# nrf7120E_enga_wificore register map
Vendor: Nordic Semiconductor; Series: nrf71; File version: 1
Registers are 32-bit, read-write, reset 0x0 unless marked. A register's access mark holds for its fields unless they carry their own. Offsets are from the block's base; [hi:lo] are bit positions; lines under a group give offsets from that group; {n}, {i} and the like mark numbered series; 'fields as' and 'values as' point back to an identical list.

## PCGCM_LRC0 — PCGC Master
Base 0x4800C000
{0xE0+4i} SETPWRCONTHRESHOLDBASE[{i}] (i=0..2) — Description collection: Set power consumption threshold base for power source / regulator n
  [3:0] SETPWRCONTHRESHOLDBASE
{0x100+4i} SETPOWERCONSUMPTIONBASE[{i}] (i=0..1) — Description collection: Set power consumption base for power/clock pair n
  [3:0] POWERREQUIREMENT
0xC00 UNLOCKBACKDOORS
  [15:0] UNLOCKBACKDOORS — Write: 0x00009375 to lock/unlock backdoors Read: 0x00000001 if backdoors is enabled Read: 0x00000000 if backdoors is disabled
0xC04 ENABLEPOWERREGFORCE
  [2:0] ENABLEPOWERREGFORCE
0xC08 POWERREGFORCE — Force reg
  [2:0] POWERREGFORCEREG
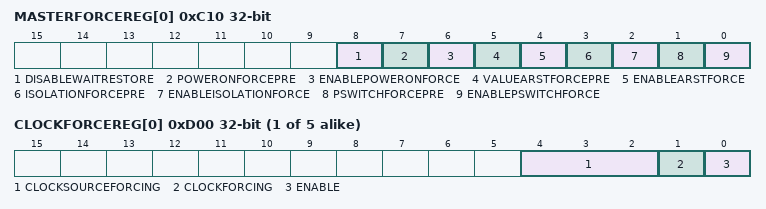
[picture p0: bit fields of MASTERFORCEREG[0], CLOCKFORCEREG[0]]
{0xC10+4i} MASTERFORCEREG[{i}] (i=0..0) — Description collection: Force reg
  [8] DISABLEWAITRESTORE — Turn off waiting for arst deactivation before retention restore
    1=Disable (Turn off waiting for arst deactivation before retention restore); 0=Enable (Wait for arst deactivation before retention restore)
  [7] POWERONFORCEPRE
  [6] ENABLEPOWERONFORCE
  [5] VALUEARSTFORCEPRE
  [4] ENABLEARSTFORCE
  [3] ISOLATIONFORCEPRE
  [2] ENABLEISOLATIONFORCE
  [1] PSWITCHFORCEPRE
  [0] ENABLEPSWITCHFORCE
{0xD00+4i} CLOCKFORCEREG[{i}] (i=0..4) — Description collection: Force clock n
  [4:2] CLOCKSOURCEFORCING
  [1] CLOCKFORCING
  [0] ENABLE — Enable clock forcing

## ANTSWC — Antenna switch controller
Base 0x4800D000
0x400 ERRORSTATUS group — Unspecified
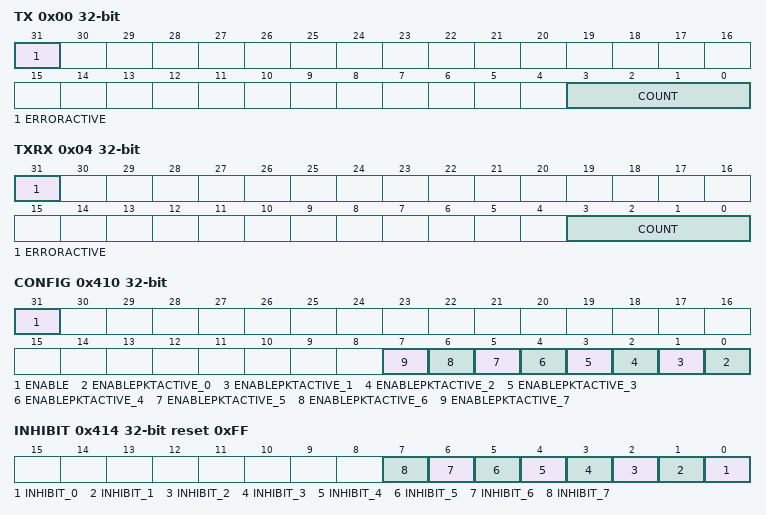
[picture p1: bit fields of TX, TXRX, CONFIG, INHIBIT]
  0x00 TX — Concurrent TX error condition
    [31] ERRORACTIVE ro — Concurrent TX error condition is active
    [3:0] COUNT — Count of concurrent TX error conditions detected
  0x04 TXRX — Concurrent TX-RX error condition
    [31] ERRORACTIVE ro — Concurrent TX-RX error condition is active
    [3:0] COUNT — Count of concurrent TX-RX error conditions detected
  0x08 ERRORPORT — Indicates which ports are in error
    [7:0] ERRORPORT — Bitfield indicating the ports in error during the last error condition.
0x410 CONFIG — Antenna switch controller enable / software reset
  [31] ENABLE — Enable antenna switch module.
    0=Disable (Antenna Switch Controller disabled - all outputs held low); 1=Enable (Antenna Switch Controller enabled)
  [n] ENABLEPKTACTIVE_{n} (n=0..7) — Bitfield indicating whether ANTSWC listens to PktActive on radio port i.
    0=Ignore PktActive on the corresponding radio port; 1=Respect (Use PktActive on the corresponding radio port for antenna switch selection)
0x414 INHIBIT reset 0xFF
  [all] fields
    0=Inhibit connection of antenna to the corresponding radio; 1=Enable antenna to be connected to the corresponding radio
  [n] INHIBIT_{n} (n=0..7) — Bitfield of 8 separate bits indicating whether connection of the antenna to radio on radio port i is enabled or inhibited.

## GLOBAL_DPPIC00 — Distributed programmable peripheral interconnect controller 0
Base 0x50042000; alternate view of GLOBAL_USBHSCORE
Same registers: GLOBAL_DPPIC10 0x50082000, GLOBAL_DPPIC20 0x500C2000, GLOBAL_DPPIC30 0x50102000
{0x0+8i} TASKS_CHG[{i}] (i=0..5) group — Channel group tasks
  0x00 EN wo — Description cluster: Enable channel group n
    [0] EN — Enable channel group n
      1=Trigger task
  0x04 DIS wo — Description cluster: Disable channel group n
    [0] DIS — Disable channel group n
      1=Trigger task
{0x80+8i} SUBSCRIBE_CHG[{i}] (i=0..5) group — Subscribe configuration for tasks
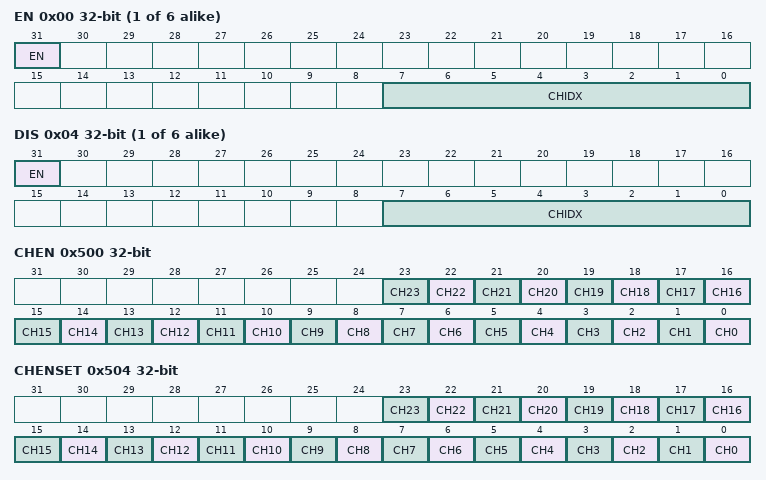
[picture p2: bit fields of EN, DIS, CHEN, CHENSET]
  0x00 EN — Description cluster: Subscribe configuration for task CHG[n].EN
    [31] EN
      0=Disabled (Disable subscription); 1=Enabled (Enable subscription)
    [7:0] CHIDX — DPPI channel that task CHG[n].EN will subscribe to
  0x04 DIS — Description cluster: Subscribe configuration for task CHG[n].DIS
    [31] EN
      values as SUBSCRIBE_CHG[0].EN.EN
    [7:0] CHIDX — DPPI channel that task CHG[n].DIS will subscribe to
0x500 CHEN — Channel enable register
  [all] fields
    0=Disabled (Disable channel); 1=Enabled (Enable channel)
  [n] CH{n} (n=0..23) — Enable or disable channel {n}
0x504 CHENSET write-1-sets — Channel enable set register
  [all] fields
    on read: 0=Disabled (Read: Channel disabled); 1=Enabled (Read: Channel enabled) | on write: 1=Set (Write: Enable channel)
  [n] CH{n} (n=0..23) — Channel {n} enable set register. Writing 0 has no effect.
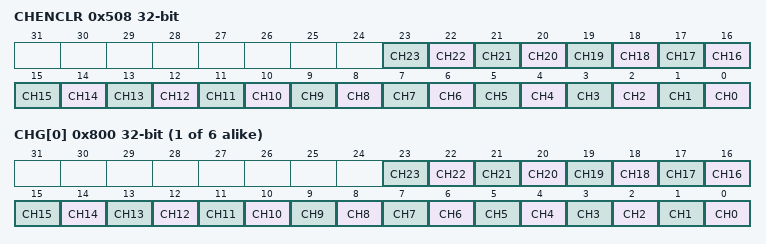
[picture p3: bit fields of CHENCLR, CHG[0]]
0x508 CHENCLR write-1-clears — Channel enable clear register
  [all] fields
    on read: 0=Disabled (Read: Channel disabled); 1=Enabled (Read: Channel enabled) | on write: 1=Clear (Write: Disable channel)
  [n] CH{n} (n=0..23) — Channel {n} enable clear register. Writing 0 has no effect.
{0x800+4i} CHG[{i}] (i=0..5) — Description collection: Channel group n Note: Writes to this register are ignored if either SUBSCRIBE_CHG[n].EN or SUBSCRIBE_CHG[n].DIS is enabled
  [all] fields
    0=Excluded; 1=Included
  [n] CH{n} (n=0..23) — Include or exclude channel {n}
